VERSION ""

NS_ :

BS_:

BU_: RadarCAN

BO_ 2316869638 Speed_: 8 Vector__XXX
 SG_ SpeedFrontAxle : 23|16@0+ (0.075,0) [0|4915.125] "km/h" Vector__XXX

BO_ 2151194636 SteerWheelAngle: 8 Vector__XXX
 SG_ SteerWheelAngle : 7|16@0+ (0.1,-772.4) [-772.4|5781.1] "deg" Vector__XXX

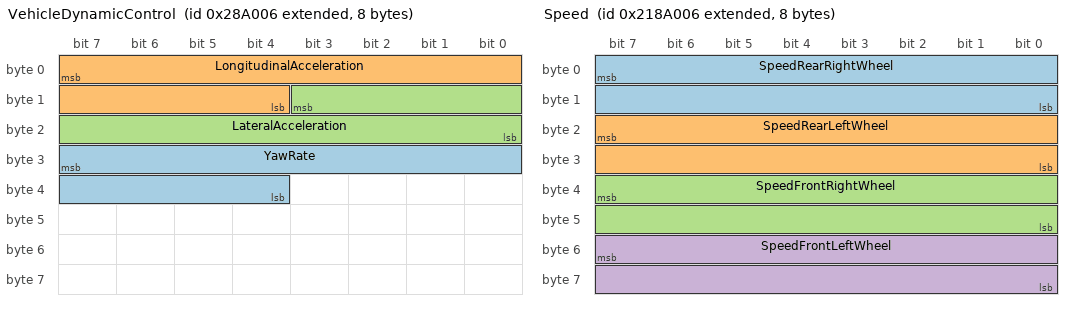
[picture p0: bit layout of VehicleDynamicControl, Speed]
BO_ 2150146054 VehicleDynamicControl: 8 Vector__XXX
 SG_ YawRate : 31|12@0+ (0.079074,-161.9292) [-161.9292|161.87883] "deg/s" Vector__XXX
 SG_ LongitudinalAcceleration : 7|12@0+ (0.02,-40.7824) [-40.7824|41.1176] "m/s2" Vector__XXX
 SG_ LateralAcceleration : 11|12@0+ (0.02,-40.96) [-40.96|40.94] "m/s2" Vector__XXX

BO_ 2316869643 Gear: 8 RadarCAN
 SG_ GearStatus : 23|8@0+ (1,0) [0|7] "" Vector__XXX

BO_ 2182651910 Speed: 8 RadarCAN
 SG_ SpeedRearRightWheel : 7|16@0+ (0.05,0) [0|1310.7] "km/h" Vector__XXX
 SG_ SpeedRearLeftWheel : 23|16@0+ (0.05,0) [0|1310.7] "km/h" Vector__XXX
 SG_ SpeedFrontRightWheel : 39|16@0+ (0.05,0) [0|1310.7] "km/h" Vector__XXX
 SG_ SpeedFrontLeftWheel : 55|16@0+ (0.05,0) [0|32767.5] "km/h" Vector__XXX

BO_ 2282790912 Turn_signal_switch: 8 RadarCAN
 SG_ TurnSignalSwitch : 28|2@0+ (1,0) [0|3] "" Vector__XXX

BA_DEF_ SG_  "GenSigSendType" ENUM  "Cyclic","OnWrite","OnWriteWithRepetition","OnChange","OnChangeWithRepetition","IfActive","IfActiveWithRepetition","NoSigSendType";
BA_DEF_ BO_  "GenMsgCycleTime" INT 0 0;
BA_DEF_ BO_  "GenMsgSendType" ENUM  "Cyclic","not_used","not_used","not_used","not_used","Cyclic","not_used","IfActive","NoMsgSendType";
BA_DEF_  "DBName" STRING ;
BA_DEF_  "BusType" STRING ;
BA_DEF_DEF_  "GenSigSendType" "Cyclic";
BA_DEF_DEF_  "GenMsgCycleTime" 0;
BA_DEF_DEF_  "GenMsgSendType" "NoMsgSendType";
BA_DEF_DEF_  "DBName" "";
BA_DEF_DEF_  "BusType" "CAN";
BA_ "DBName" "Autel_Fiat";
BA_ "GenMsgCycleTime" BO_ 2316869643 20;
VAL_ 2316869643 GearStatus 128 "D" 126 "N" 92 "R" 58 "P" 0 "hang in the air" ;
VAL_ 2282790912 TurnSignalSwitch 3 "Undefined" 2 "Left turn to be Flashing" 1 "Right Turn to be Flashing" 0 "No Turn being signaled" ;
